# PIC32MZ2051W104132 device description
Architecture: MIPS; Family: PIC32MZW; Series: PIC32MZW
Registers are 32-bit, read-write, no defined reset value unless marked. A register's access mark holds for its fields unless they carry their own. Offsets are from the block's base; [hi:lo] are bit positions; {n}, {i} and the like mark numbered series; 'fields as' and 'values as' point back to an identical list.

## OCMP
Instances: OCMP 0x1f842000 in periph_pb3
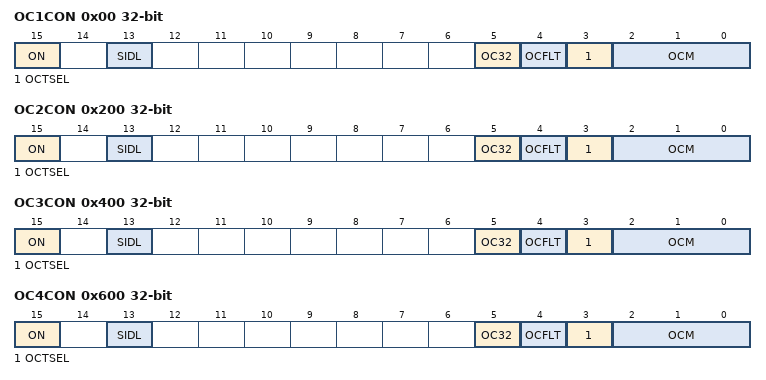
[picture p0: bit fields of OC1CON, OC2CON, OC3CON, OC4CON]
0x00 OC1CON — Output Compare 'x' Control Register
  [15] ON — Output Compare Peripheral On bit
    1=Output Compare peripheral is enabled; 0=Output Compare peripheral is disabled
  [13] SIDL — Stop in Idle Mode bit
    1=Discontinue operation when CPU enters Idle mode; 0=Continue operation in Idle mode
  [5] OC32 — 32-bit Compare Mode bit
    1=OCxR(31-0) and/or OCxRS(31-0) are used for comparisions to the 32-bit timer source; 0=OCxR(15-0) and OCxRS(15-0) are used for comparisons to the 16-bit timer source
  [4] OCFLT — PWM Fault Condition Status bit
    1=PWM Fault condition has occurred (cleared in HW only); 0=No PWM Fault condition has occurred
  [3] OCTSEL — Output Compare Timer Select bit
    1=Timer3 is the clock source for this Output Compare module; 0=Timer2 is the clock source for this Output Compare module
  [2:0] OCM — Output Compare Mode Select bits
    7=PWM mode on OCx; Fault pin enabled; 6=PWM mode on OCx; Fault pin disabled; 5=Initialize OCx pin low; generate continious output pulses on OCx pin; 4=Initialize OCx pin low: generate single output pulse on OCx pin; 3=Compare event toggles OCx pin; 2=Initialize OCx pin high; compare event forces OCx pin low; 1=Initialize OCx pin low; compare event forces OCx pin high; 0=Output compare peripheral is disabled but continues to draw current
0x10 OC1R
0x20 OC1RS
0x200 OC2CON — Output Compare 'x' Control Register
  fields as OC1CON
0x210 OC2R
0x220 OC2RS
0x400 OC3CON — Output Compare 'x' Control Register
  fields as OC1CON
0x410 OC3R
0x420 OC3RS
0x600 OC4CON — Output Compare 'x' Control Register
  fields as OC1CON
0x610 OC4R
0x620 OC4RS

## PCACHE
Instances: PCACHE 0x1f812400 in periph_pb1b
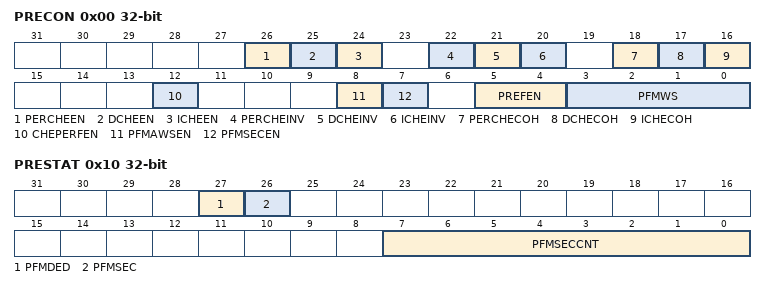
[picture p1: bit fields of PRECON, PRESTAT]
0x00 PRECON
  [26] PERCHEEN — Peripheral Cache Enable bit
    1=Peripheral cache is enabled; 0=Peripheral cache is disabled
  [25] DCHEEN — Data Cache Enable bit
    1=Data cache is enabled; 0=Data cache is disabled
  [24] ICHEEN — Instruction Cache Enable bit
    1=Instruction cache is enabled; 0=Instruction cache is disabled
  [22] PERCHEINV — Peripheral Cache Invalidate bit
    1=Force invalidate cache/invalidate busy; 0=Cache Invalidation follows CHECOH/invalid complete
  [21] DCHEINV — Data Cache Invalidate bit
    values as PERCHEINV
  [20] ICHEINV — Instruction Cache Invalidate bit
    values as PERCHEINV
  [18] PERCHECOH — Peripheral Auto-cache Coherency Control bit
    1=Automatically invalidate cache on a programming event; 0=Do not automatically invalidate cache on a programming event
  [17] DCHECOH — Data Auto-cache Coherency Control bit
    values as PERCHECOH
  [16] ICHECOH — Instruction Auto-cache Coherency Control bit
    values as PERCHECOH
  [12] CHEPERFEN — Cache Performance Counters Enable bit
    1=Performance counters are enabled; 0=Performance counters are disabled
  [8] PFMAWSEN — PFM Address Wait State Enable bit
    1=Add one more Wait State to flash address setup (suggested for higher system clock frequencies); 0=Add no Wait States to the flash address setup (suggested for lower system clock frequencies to achieve higher performance)
  [7] PFMSECEN
  [5:4] PREFEN — Predictive Prefetch Enable bits
    1=Enable predictive prefetch for CPU instructions only; 0=Disable predictive prefetch
  [3:0] PFMWS — PFM Access Time Defined in Terms of SYSCLK Wait States bits
    7=Seven Wait states; 6=Six Wait states; 5=Five Wait states; 4=Four Wait states; 3=Three Wait states; 2=Two Wait states; 1=One Wait state; 0=Zero Wait states
0x10 PRESTAT
  [27] PFMDED, [26] PFMSEC, [7:0] PFMSECCNT
0x20 PREHIT ro
  [31:0] CHEHIT
0x30 PREMIS ro
  [31:0] CHEMIS

## PMU
Instances: PMU 0x1f813e00 in periph_pb1b
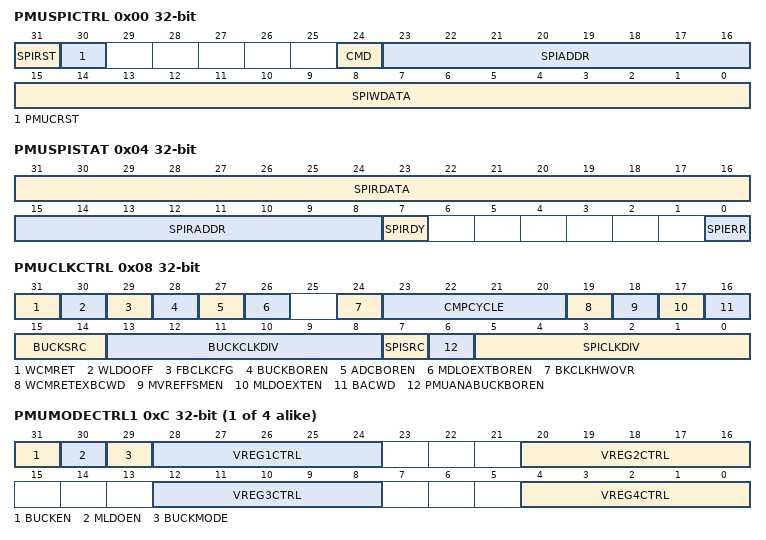
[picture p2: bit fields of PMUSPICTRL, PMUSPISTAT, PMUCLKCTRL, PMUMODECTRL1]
0x00 PMUSPICTRL
  [31] SPIRST, [30] PMUCRST, [24] CMD, [23:16] SPIADDR, [15:0] SPIWDATA
0x04 PMUSPISTAT
  [31:16] SPIRDATA, [15:8] SPIRADDR, [7] SPIRDY, [0] SPIERR
0x08 PMUCLKCTRL
  [31] WCMRET, [30] WLDOOFF, [29] FBCLKCFG, [28] BUCKBOREN, [27] ADCBOREN, [26] MDLOEXTBOREN, [24] BKCLKHWOVR, [23:20] CMPCYCLE, [19] WCMRETEXBCWD, [18] MVREFFSMEN, [17] MLDOEXTEN, [16] BACWD, [15:14] BUCKSRC, [13:8] BUCKCLKDIV, [7] SPISRC, [6] PMUANABUCKBOREN, [5:0] SPICLKDIV
{0x8+4i} PMUMODECTRL{i} (i=1..4)
  [31] BUCKEN, [30] MLDOEN, [29] BUCKMODE, [36-8n:32-8n] VREG{n}CTRL (n=1..4)
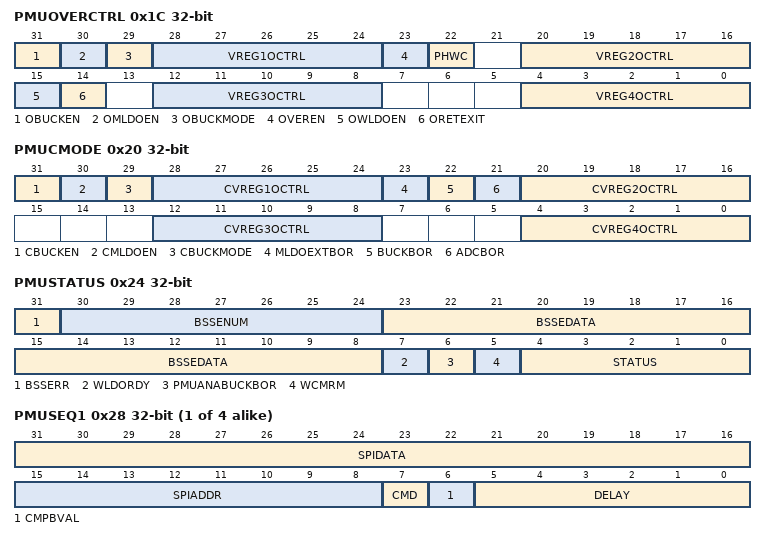
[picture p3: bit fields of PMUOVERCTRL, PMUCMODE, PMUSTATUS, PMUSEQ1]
0x1C PMUOVERCTRL
  [31] OBUCKEN, [30] OMLDOEN, [29] OBUCKMODE, [36-8n:32-8n] VREG{n}OCTRL (n=1..4), [23] OVEREN, [22] PHWC, [15] OWLDOEN, [14] ORETEXIT
0x20 PMUCMODE ro
  [31] CBUCKEN, [30] CMLDOEN, [29] CBUCKMODE, [36-8n:32-8n] CVREG{n}OCTRL (n=1..4), [23] MLDOEXTBOR, [22] BUCKBOR, [21] ADCBOR
0x24 PMUSTATUS ro
  [31] BSSERR, [30:24] BSSENUM, [23:8] BSSEDATA, [7] WLDORDY, [6] PMUANABUCKBOR, [5] WCMRM, [4:0] STATUS
{0x24+4i} PMUSEQ{i} ro (i=1..4)
  [31:16] SPIDATA, [15:8] SPIADDR, [7] CMD, [6] CMPBVAL, [5:0] DELAY
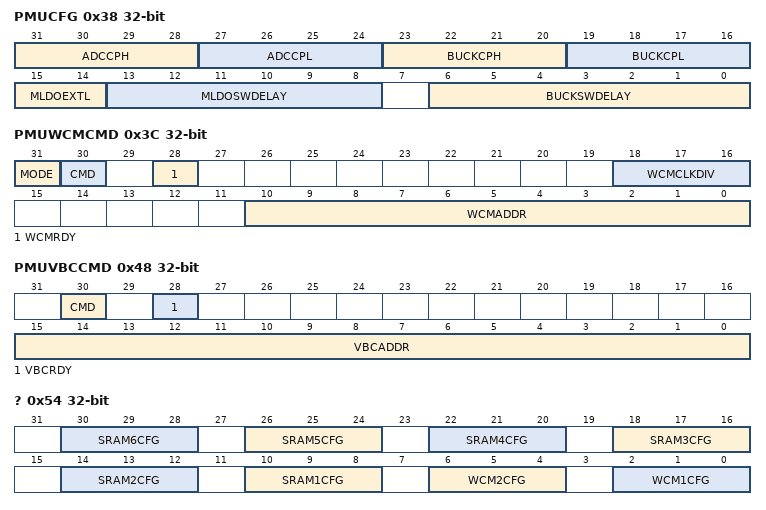
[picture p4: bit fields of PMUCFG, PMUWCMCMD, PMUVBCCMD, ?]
0x38 PMUCFG ro
  [31:28] ADCCPH, [27:24] ADCCPL, [23:20] BUCKCPH, [19:16] BUCKCPL, [15:14] MLDOEXTL, [13:8] MLDOSWDELAY, [6:0] BUCKSWDELAY
0x3C PMUWCMCMD
  [31] MODE, [30] CMD, [28] WCMRDY, [18:16] WCMCLKDIV, [10:0] WCMADDR
0x40 PMUWCMWDATA
  [31:0] WDATA
0x44 PMUWCMRDATA
  [31:0] RDATA
0x48 PMUVBCCMD
  [30] CMD, [28] VBCRDY, [15:0] VBCADDR
0x4C PMUVCBWDATA
  [31:0] WDATA
0x50 ? — PMUVCBRDATA
  [31:0] RDATA
0x54 ? — WCMCFG
  [4n+6:4n+4] SRAM{n}CFG (n=1..6), [6:4] WCM2CFG, [2:0] WCM1CFG
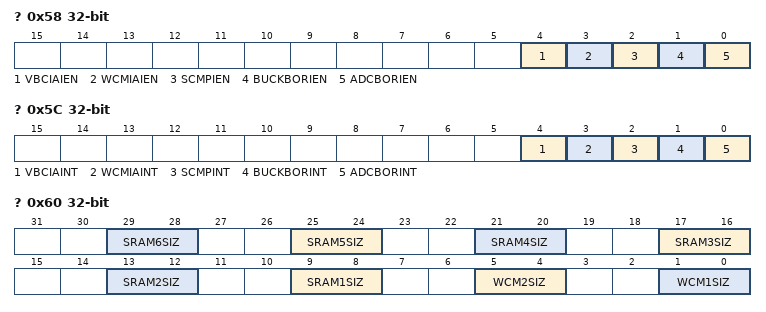
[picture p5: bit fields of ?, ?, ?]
0x58 ? — PMUIENB
  [4] VBCIAIEN, [3] WCMIAIEN, [2] SCMPIEN, [1] BUCKBORIEN, [0] ADCBORIEN
0x5C ? — PMUISTAT
  [4] VBCIAINT, [3] WCMIAINT, [2] SCMPINT, [1] BUCKBORINT, [0] ADCBORINT
0x60 ? — WCMSIZ
  [4n+5:4n+4] SRAM{n}SIZ (n=1..6), [5:4] WCM2SIZ, [1:0] WCM1SIZ
0x200 ? — PMUWCM
  [31:0] WCMDATA
